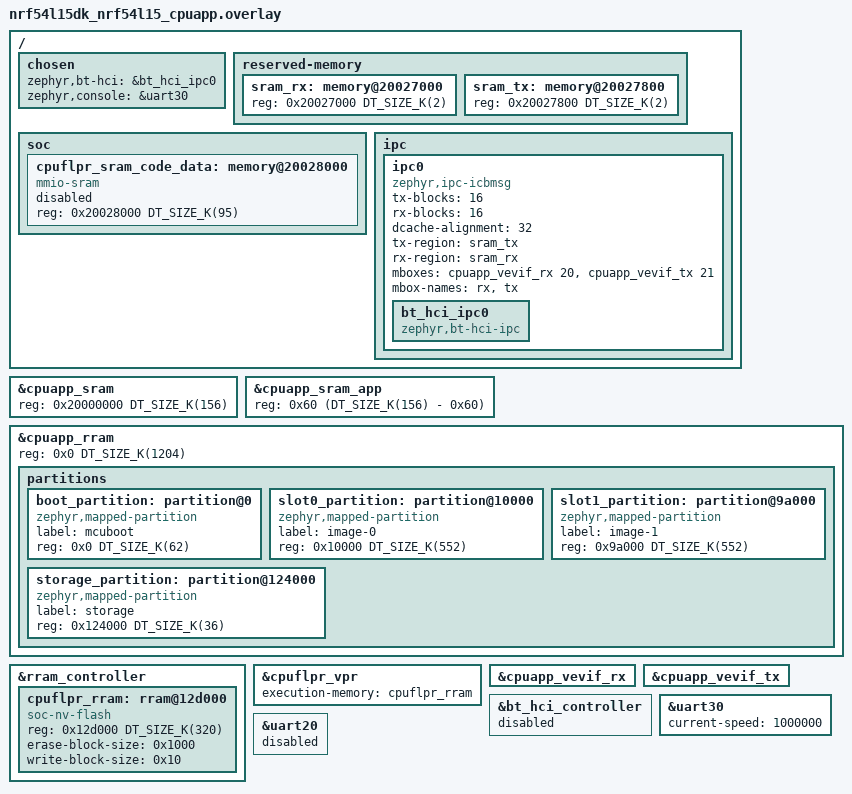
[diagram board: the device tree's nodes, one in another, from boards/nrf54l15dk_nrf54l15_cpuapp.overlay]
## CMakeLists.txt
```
# SPDX-License-Identifier: Apache-2.0

cmake_minimum_required(VERSION 3.20.0)
find_package(Zephyr REQUIRED HINTS $ENV{ZEPHYR_BASE})
project(observer_broadcaster_multiple)

target_sources(app PRIVATE
  src/main.c
  ../observer/src/observer.c
  ../broadcaster_multiple/src/broadcaster_multiple.c
)
```

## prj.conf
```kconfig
CONFIG_BT=y
CONFIG_BT_DEVICE_NAME="Observer Broadcaster"

# Enable Broadcaster Role
CONFIG_BT_BROADCASTER=y
CONFIG_BT_EXT_ADV=y
CONFIG_BT_EXT_ADV_MAX_ADV_SET=4

# Enable Peripheral Role
CONFIG_BT_PERIPHERAL=y
CONFIG_BT_MAX_CONN=1

# Enable Observer Role
CONFIG_BT_OBSERVER=y

# Enable Extended Scanning
CONFIG_BT_EXT_ADV=y
CONFIG_BT_EXT_SCAN_BUF_SIZE=1650

# BT Buffers
CONFIG_BT_BUF_CMD_TX_SIZE=255
CONFIG_BT_BUF_EVT_RX_COUNT=4
CONFIG_BT_BUF_EVT_RX_SIZE=255
CONFIG_BT_BUF_ACL_TX_COUNT=3
CONFIG_BT_BUF_ACL_TX_SIZE=251
CONFIG_BT_BUF_ACL_RX_COUNT_EXTRA=1
CONFIG_BT_BUF_ACL_RX_SIZE=255

CONFIG_THREAD_ANALYZER=y
CONFIG_THREAD_ANALYZER_AUTO=y
CONFIG_THREAD_ANALYZER_AUTO_INTERVAL=5
CONFIG_THREAD_NAME=y

CONFIG_LOG=y
CONFIG_LOG_BUFFER_SIZE=4096
```

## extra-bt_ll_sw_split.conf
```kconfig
# Enable Broadcaster Role
CONFIG_BT_BROADCASTER=y
CONFIG_BT_EXT_ADV=y

# Enable Peripheral Role
CONFIG_BT_PERIPHERAL=y
CONFIG_BT_MAX_CONN=1

# Enable Observer Role
CONFIG_BT_OBSERVER=y

# Enable legacy, 2M, 1M and Coded PHY advertising
CONFIG_BT_EXT_ADV_MAX_ADV_SET=4

# Zephyr Bluetooth LE Controller will need to use chain PDUs when AD data
# length > 191 bytes
# - 31 bytes will use 22 bytes for the default name in this sample plus 9 bytes
#   for manufacturer data
# - 191 bytes will use 22 bytes for the default name in this sample plus 169
#   bytes for manufacturer data
# - 277 bytes will use 22 bytes for the default name in this sample plus 255
#   bytes for manufacturer data
CONFIG_BT_CTLR_ADV_DATA_LEN_MAX=255

# Enable Coded PHY feature
CONFIG_BT_CTLR_PHY_CODED=y

# BT Buffers for Extended Scanning when using Zephyr Controller
CONFIG_BT_BUF_CMD_TX_SIZE=255
# Zephyr Bluetooth LE Controller needs 16 event buffers to generate Extended
# Advertising Report for receiving the complete 1650 bytes of data
CONFIG_BT_BUF_EVT_RX_COUNT=16
CONFIG_BT_BUF_EVT_RX_SIZE=255
CONFIG_BT_BUF_ACL_TX_COUNT=3
CONFIG_BT_BUF_ACL_TX_SIZE=251
CONFIG_BT_BUF_ACL_RX_COUNT_EXTRA=1
CONFIG_BT_BUF_ACL_RX_SIZE=255

# Set maximum scan data length for Extended Scanning in Bluetooth LE Controller
CONFIG_BT_CTLR_SCAN_DATA_LEN_MAX=1650

# Increase Zephyr Bluetooth LE Controller Rx buffer to receive complete chain
# of PDUs
CONFIG_BT_CTLR_RX_BUFFERS=9

# Zephyr Controller Advanced Features
CONFIG_BT_CTLR_ADVANCED_FEATURES=y

# Increase Advertising PDU buffers to number of advertising sets times the
# number of chain PDUs per advertising set when using Zephyr Bluetooth LE
# Controller
CONFIG_BT_CTLR_ADV_DATA_BUF_MAX=6
CONFIG_BT_CTLR_ADV_DATA_CHAIN=y

# Increase the below to receive interleaved advertising chains
CONFIG_BT_CTLR_SCAN_AUX_SET=3
CONFIG_BT_CTLR_LOW_LAT_ULL=y
# CONFIG_BT_CTLR_SCAN_AUX_USE_CHAINS=y
# CONFIG_BT_CTLR_SCAN_AUX_CHAIN_COUNT=3

CONFIG_BT_CTLR_ADV_RESERVE_MAX=n
CONFIG_BT_CTLR_ADV_SLOT_WINDOW=y
CONFIG_BT_CTLR_ADV_AUX_SLOT_WINDOW_DRIFT=y
CONFIG_BT_CTLR_SCAN_UNRESERVED=y
CONFIG_BT_CTLR_SCAN_SLOT_WINDOW=y
CONFIG_BT_CTLR_SCAN_AUX_SYNC_RESERVE_MIN=y
CONFIG_BT_CTLR_SYNC_PERIODIC_SKIP_ON_SCAN_AUX=n
CONFIG_BT_CTLR_CENTRAL_RESERVE_MAX=n
CONFIG_BT_CTLR_PERIPHERAL_RESERVE_MAX=n
CONFIG_BT_CTLR_EVENT_OVERHEAD_RESERVE_MAX=y
CONFIG_BT_CTLR_SLOT_RESERVATION_UPDATE=n
CONFIG_BT_TICKER_NEXT_SLOT_GET_MATCH=y
CONFIG_BT_TICKER_EXT=y
CONFIG_BT_TICKER_EXT_EXPIRE_INFO=n
CONFIG_BT_TICKER_EXT_SLOT_WINDOW_YIELD=y

CONFIG_BT_CTLR_LLL_PRIO=0
CONFIG_BT_CTLR_ULL_HIGH_PRIO=1
CONFIG_BT_CTLR_ULL_LOW_PRIO=2

CONFIG_BT_CTLR_LLL_PREPARE_AT_MARGIN=y
CONFIG_BT_CTLR_RADIO_TIMER_ISR=y
CONFIG_BT_CTLR_SW_SWITCH_SINGLE_TIMER=n

# CONFIG_ZERO_LATENCY_IRQS=y
# CONFIG_BT_CTLR_ZLI=y

# Enable in-system tests and profiling
# CONFIG_BT_CTLR_TEST=y
CONFIG_BT_CTLR_PROFILE_ISR=y

# Use link time optimization for code size reduction
CONFIG_ISR_TABLES_LOCAL_DECLARATION=y
CONFIG_LTO=y

# Generate .lst file, to find HCI h/w error event given PC
CONFIG_OUTPUT_DISASSEMBLY=y
CONFIG_OUTPUT_DISASSEMBLY_WITH_SOURCE=y

CONFIG_BT_CTLR_ASSERT_OPTIMIZE_FOR_SIZE=n

CONFIG_THREAD_ANALYZER=y
CONFIG_THREAD_ANALYZER_AUTO=y
CONFIG_THREAD_ANALYZER_AUTO_INTERVAL=5
CONFIG_THREAD_NAME=y

CONFIG_LOG=y
CONFIG_LOG_BUFFER_SIZE=4096
```

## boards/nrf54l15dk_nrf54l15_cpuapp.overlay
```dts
/*
 * Copyright (c) 2026 Nordic Semiconductor ASA
 *
 * SPDX-License-Identifier: Apache-2.0
 */

/*
 * Must match samples/bluetooth/hci_ipc/boards/nrf54l15dk_nrf54l15_cpuflpr.overlay
 *
 * RRAM: 1204 (APP) + 320 (FLPR) = 1524KB
 * RAM:  156 (APP) + 4 (IPC) + 95 (FLPR) + 1 (unused) = 256KB
 */

/ {
	chosen {
		zephyr,bt-hci = &bt_hci_ipc0;
		zephyr,console = &uart30;
	};

	reserved-memory {
		sram_rx: memory@20027000 {
			reg = <0x20027000 DT_SIZE_K(2)>;
		};

		sram_tx: memory@20027800 {
			reg = <0x20027800 DT_SIZE_K(2)>;
		};
	};

	soc {
		cpuflpr_sram_code_data: memory@20028000 {
			compatible = "mmio-sram";
			reg = <0x20028000 DT_SIZE_K(95)>;
			ranges = <0x0 0x20028000 DT_SIZE_K(95)>;
			status = "reserved";
			#address-cells = <1>;
			#size-cells = <1>;
		};
	};

	ipc {
		ipc0: ipc0 {
			compatible = "zephyr,ipc-icbmsg";
			tx-blocks = <16>;
			rx-blocks = <16>;
			dcache-alignment = <32>;
			tx-region = <&sram_tx>;
			rx-region = <&sram_rx>;
			mboxes = <&cpuapp_vevif_rx 20>, <&cpuapp_vevif_tx 21>;
			mbox-names = "rx", "tx";
			status = "okay";

			bt_hci_ipc0: bt_hci_ipc0 {
				compatible = "zephyr,bt-hci-ipc";
				status = "okay";
			};
		};
	};
};

&cpuapp_sram {
	reg = <0x20000000 DT_SIZE_K(156)>;
	ranges = <0x0 0x20000000 DT_SIZE_K(156)>;
};

&cpuapp_sram_app {
	reg = <0x60 (DT_SIZE_K(156) - 0x60)>;
};

&cpuapp_rram {
	reg = <0x0 DT_SIZE_K(1204)>;
	ranges = <0x0 0x0 DT_SIZE_K(1204)>;

	/delete-node/ partitions;

	partitions {
		ranges;
		#address-cells = <1>;
		#size-cells = <1>;

		boot_partition: partition@0 {
			compatible = "zephyr,mapped-partition";
			label = "mcuboot";
			reg = <0x0 DT_SIZE_K(62)>;
		};

		slot0_partition: partition@10000 {
			compatible = "zephyr,mapped-partition";
			label = "image-0";
			reg = <0x10000 DT_SIZE_K(552)>;
		};

		slot1_partition: partition@9a000 {
			compatible = "zephyr,mapped-partition";
			label = "image-1";
			reg = <0x9a000 DT_SIZE_K(552)>;
		};

		storage_partition: partition@124000 {
			compatible = "zephyr,mapped-partition";
			label = "storage";
			reg = <0x124000 DT_SIZE_K(36)>;
		};
	};
};

&rram_controller {
	cpuflpr_rram: rram@12d000 {
		compatible = "soc-nv-flash";
		reg = <0x12d000 DT_SIZE_K(320)>;
		ranges = <0x0 0x12d000 DT_SIZE_K(320)>;
		erase-block-size = <0x1000>;
		write-block-size = <0x10>;
		#address-cells = <1>;
		#size-cells = <1>;
	};
};

&cpuflpr_vpr {
	status = "okay";
	execution-memory = <&cpuflpr_rram>;
	/*
	 * execution-memory = <&cpuflpr_sram_code_data>;
	 * source-memory = <&cpuflpr_rram>;
	 */
};

&cpuapp_vevif_rx {
	status = "okay";
};

&cpuapp_vevif_tx {
	status = "okay";
};

&bt_hci_controller {
	status = "disabled";
};

&uart30 {
	current-speed = <1000000>;
	status = "okay";
};

&uart20 {
	status = "disabled";
};
```

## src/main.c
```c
/*
 * Copyright (c) 2024 Nordic Semiconductor ASA
 *
 * SPDX-License-Identifier: Apache-2.0
 */

#include <zephyr/sys/printk.h>
#include <zephyr/bluetooth/bluetooth.h>
#include <zephyr/bluetooth/conn.h>

int observer_start(void);
int broadcaster_multiple(void);

enum {
	STATE_CONNECTED,
	STATE_DISCONNECTED,

	STATE_BITS,
};

static ATOMIC_DEFINE(state, STATE_BITS);

static void connected(struct bt_conn *conn, uint8_t err)
{
	if (err) {
		printk("Connection failed, err 0x%02x\n", err);
	} else {
		printk("Connected\n");

		(void)atomic_set_bit(state, STATE_CONNECTED);
	}
}

static void disconnected(struct bt_conn *conn, uint8_t reason)
{
	printk("Disconnected, reason 0x%02x\n", reason);

	(void)atomic_set_bit(state, STATE_DISCONNECTED);
}

BT_CONN_CB_DEFINE(conn_callbacks) = {
	.connected = connected,
	.disconnected = disconnected,
};

int main(void)
{
	int err;

	printk("Starting Observer Broadcaster Demo\n");

	/* Initialize the Bluetooth Subsystem */
	err = bt_enable(NULL);
	if (err) {
		printk("Bluetooth init failed (err %d)\n", err);
		return 0;
	}

	(void)broadcaster_multiple();
	(void)observer_start();

	while (1) {
		k_sleep(K_SECONDS(1));

		if (atomic_test_and_clear_bit(state, STATE_CONNECTED)) {
			/* Connected callback executed */

		} else if (atomic_test_and_clear_bit(state, STATE_DISCONNECTED)) {
			extern struct bt_le_ext_adv *broadcaster_multiple_connectable_get(void);
			struct bt_le_ext_adv *adv = broadcaster_multiple_connectable_get();

			printk("Starting Legacy Connectable Advertising...\n");
			err = bt_le_ext_adv_start(adv, BT_LE_EXT_ADV_START_DEFAULT);
			if (err) {
				printk("Failed to start extended advertising set (err %d)\n", err);
				return 0;
			}
		}
	}

	return 0;
}
```
